VERSION "HIPBNYYYYYYYYYYYYYYYYYYYYYYYYYYYYYYYYYYYYY/4/%%%/4/'%**4YYY///"

NS_ :

BS_:

BU_:

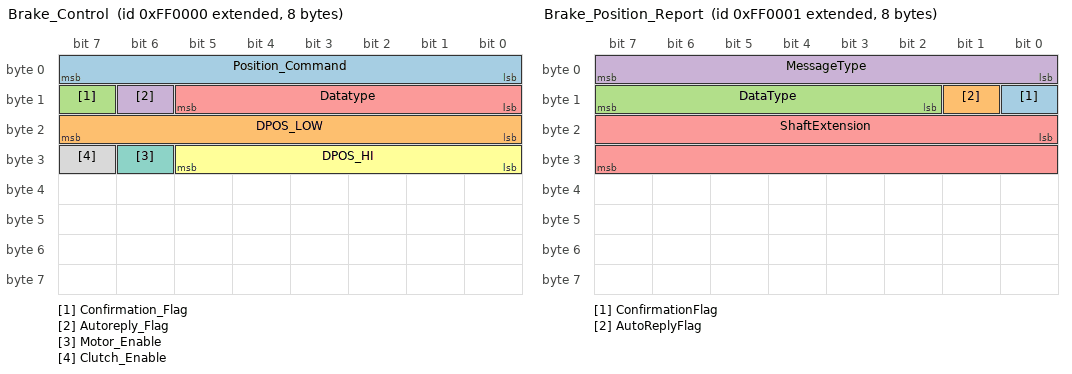
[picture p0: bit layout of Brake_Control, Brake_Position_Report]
BO_ 2164195328 Brake_Control: 8 Vector__XXX
 SG_ Position_Command : 0|8@1+ (1,0) [0|0] "" Vector__XXX
 SG_ DPOS_LOW : 16|8@1+ (1,0) [0|0] "" Vector__XXX
 SG_ Confirmation_Flag : 15|1@1+ (1,0) [0|0] "" Vector__XXX
 SG_ Autoreply_Flag : 14|1@1+ (1,0) [0|0] "" Vector__XXX
 SG_ Datatype : 8|6@1+ (1,0) [0|0] "" Vector__XXX
 SG_ DPOS_HI : 24|6@1+ (1,0) [0|0] "" Vector__XXX
 SG_ Motor_Enable : 30|1@1+ (1,0) [0|0] "" Vector__XXX
 SG_ Clutch_Enable : 31|1@1+ (1,0) [0|0] "" Vector__XXX

BO_ 2164195329 Brake_Position_Report: 8 Vector__XXX
 SG_ ConfirmationFlag : 8|1@1+ (1,0) [0|0] "" Vector__XXX
 SG_ AutoReplyFlag : 9|1@1+ (1,0) [0|0] "" Vector__XXX
 SG_ DataType : 10|6@1+ (1,0) [0|0] "" Vector__XXX
 SG_ MessageType : 0|8@1+ (1,0) [0|0] "" Vector__XXX
 SG_ ShaftExtension : 16|16@1+ (1,0) [0|0] "" Vector__XXX
